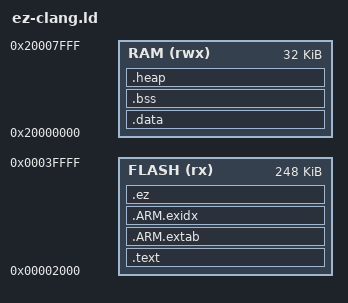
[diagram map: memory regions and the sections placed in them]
/*
  Copyright (c) 2014-2015 Arduino LLC.  All right reserved.

  This library is free software; you can redistribute it and/or
  modify it under the terms of the GNU Lesser General Public
  License as published by the Free Software Foundation; either
  version 2.1 of the License, or (at your option) any later version.

  This library is distributed in the hope that it will be useful,
  but WITHOUT ANY WARRANTY; without even the implied warranty of
  MERCHANTABILITY or FITNESS FOR A PARTICULAR PURPOSE.
  See the GNU Lesser General Public License for more details.

  You should have received a copy of the GNU Lesser General Public
  License along with this library; if not, write to the Free Software
  Foundation, Inc., 51 Franklin St, Fifth Floor, Boston, MA  02110-1301  USA
*/

/* Linker script to configure memory regions.
 * Need modifying for a specific board.
 *   FLASH.ORIGIN: starting address of flash
 *   FLASH.LENGTH: length of flash
 *   RAM.ORIGIN: starting address of RAM bank 0
 *   RAM.LENGTH: length of RAM bank 0
 */
MEMORY
{
  FLASH (rx) : ORIGIN = 0x00000000+0x2000, LENGTH = 0x00040000-0x2000 /* First 8KB used by bootloader */
  RAM (rwx) : ORIGIN = 0x20000000, LENGTH = 0x00008000
}

/* Linker script to place sections and symbol values. Should be used together
 * with other linker script that defines memory regions FLASH and RAM.
 * It references following symbols, which must be defined in code:
 *   Reset_Handler : Entry of reset handler
 *
 * It defines following symbols, which code can use without definition:
 *   __exidx_start
 *   __exidx_end
 *   __copy_table_start__
 *   __copy_table_end__
 *   __zero_table_start__
 *   __zero_table_end__
 *   __etext
 *   __data_start__
 *   __preinit_array_start
 *   __preinit_array_end
 *   __init_array_start
 *   __init_array_end
 *   __fini_array_start
 *   __fini_array_end
 *   __data_end__
 *   __bss_start__
 *   __bss_end__
 *   __end__
 *   end
 *   __HeapLimit
 *   __StackLimit
 *   __StackTop
 *   __stack
 */
ENTRY(Reset_Handler)

SECTIONS
{
	.text :
	{
		__text_start__ = .;

		KEEP(*(.isr_vector))
		*(.text*)

		KEEP(*(.init))
		KEEP(*(.fini))

		/* .ctors */
		*crtbegin.o(.ctors)
		*crtbegin?.o(.ctors)
		*(EXCLUDE_FILE(*crtend?.o *crtend.o) .ctors)
		*(SORT(.ctors.*))
		*(.ctors)

		/* .dtors */
 		*crtbegin.o(.dtors)
 		*crtbegin?.o(.dtors)
 		*(EXCLUDE_FILE(*crtend?.o *crtend.o) .dtors)
 		*(SORT(.dtors.*))
 		*(.dtors)

		*(.rodata*)

		KEEP(*(.eh_frame*))
	} > FLASH

	.ARM.extab :
	{
		*(.ARM.extab* .gnu.linkonce.armextab.*)
	} > FLASH

	__exidx_start = .;
	.ARM.exidx :
	{
		*(.ARM.exidx* .gnu.linkonce.armexidx.*)
	} > FLASH
	__exidx_end = .;

  .ez :
  {
    . = ALIGN(4);
    _ssymtab = .;
    KEEP (*(.ez.symtab))
    _esymtab = .;

    . = ALIGN(4);
    _sstrtab = .;
    KEEP (*(.ez.strtab))
    _estrtab = .;
  } > FLASH

	__etext = .;

	.data : AT (__etext)
	{
		__data_start__ = .;
		*(vtable)
		*(.data*)

		. = ALIGN(4);
		/* preinit data */
		PROVIDE_HIDDEN (__preinit_array_start = .);
		KEEP(*(.preinit_array))
		PROVIDE_HIDDEN (__preinit_array_end = .);

		. = ALIGN(4);
		/* init data */
		PROVIDE_HIDDEN (__init_array_start = .);
		KEEP(*(SORT(.init_array.*)))
		KEEP(*(.init_array))
		PROVIDE_HIDDEN (__init_array_end = .);


		. = ALIGN(4);
		/* finit data */
		PROVIDE_HIDDEN (__fini_array_start = .);
		KEEP(*(SORT(.fini_array.*)))
		KEEP(*(.fini_array))
		PROVIDE_HIDDEN (__fini_array_end = .);

		KEEP(*(.jcr*))
		. = ALIGN(16);
		/* All data end */
		__data_end__ = .;

	} > RAM

	.bss :
	{
		. = ALIGN(4);
		__bss_start__ = .;
		*(.bss*)
		*(COMMON)
		. = ALIGN(4);
		__bss_end__ = .;
	} > RAM

	.heap (COPY):
	{
    __end__ = .;
    PROVIDE(end = .);
		*(.heap*)
		__HeapLimit = .;
	} > RAM

  /* Reserve remaining memory for JITed code buffer
	 * FIXME: 16 byte alignment should be fine, but it caused issue for interrupt-
	 * 				based serial I/O. This workaround adds a 4k alignment to provide
	 *				enough padding in front of the code buffer. */
  . = ALIGN(4096);
  __CodeBuffer = .;

  __StackTop = ORIGIN(RAM) + LENGTH(RAM);
  __StackLimit = __StackTop - 0x400;
  PROVIDE(__stack = __StackTop);
  PROVIDE(_sstack = __StackLimit);
  PROVIDE(_estack = __StackTop);
  PROVIDE(_scode_buffer = __CodeBuffer);
  PROVIDE(_ecode_buffer = __StackLimit);

	__ram_end__ = ORIGIN(RAM) + LENGTH(RAM) - 1;

	/* Check if data + heap + stack exceeds RAM limit */
	ASSERT(__StackLimit >= __HeapLimit, "region RAM overflowed with stack")
}
